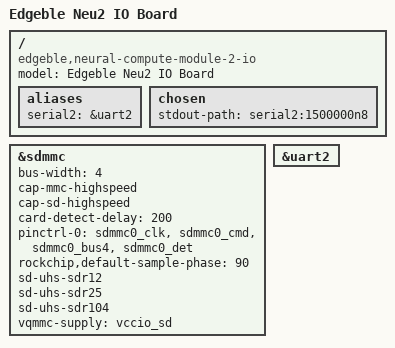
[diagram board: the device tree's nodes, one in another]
// SPDX-License-Identifier: (GPL-2.0+ OR MIT)
/*
 * Copyright (c) 2020 Rockchip Electronics Co., Ltd.
 * Copyright (c) 2022 Edgeble AI Technologies Pvt. Ltd.
 */

/dts-v1/;
#include "rv1126.dtsi"
#include "rv1126-edgeble-neu2.dtsi"

/ {
	model = "Edgeble Neu2 IO Board";
	compatible = "edgeble,neural-compute-module-2-io",
		     "edgeble,neural-compute-module-2", "rockchip,rv1126";

	aliases {
		serial2 = &uart2;
	};

	chosen {
		stdout-path = "serial2:1500000n8";
	};
};

&sdmmc {
	bus-width = <4>;
	cap-mmc-highspeed;
	cap-sd-highspeed;
	card-detect-delay = <200>;
	pinctrl-names = "default";
	pinctrl-0 = <&sdmmc0_clk &sdmmc0_cmd &sdmmc0_bus4 &sdmmc0_det>;
	rockchip,default-sample-phase = <90>;
	sd-uhs-sdr12;
	sd-uhs-sdr25;
	sd-uhs-sdr104;
	vqmmc-supply = <&vccio_sd>;
	status = "okay";
};

&uart2 {
	status = "okay";
};
